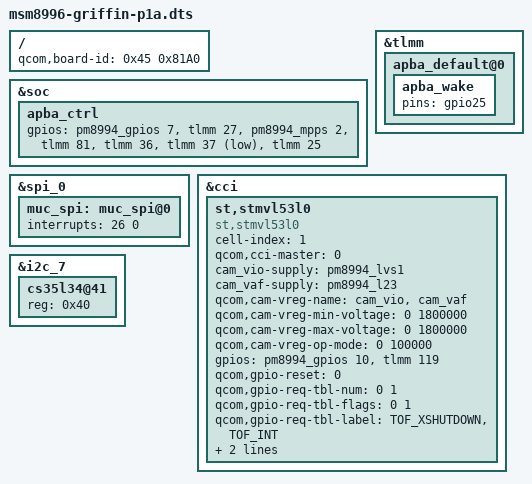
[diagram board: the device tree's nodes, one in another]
/* Copyright (c) 2015, Motorola Mobility Inc. All rights reserved.
 *
 * This program is free software; you can redistribute it and/or modify
 * it under the terms of the GNU General Public License version 2 and
 * only version 2 as published by the Free Software Foundation.
 *
 * This program is distributed in the hope that it will be useful,
 * but WITHOUT ANY WARRANTY; without even the implied warranty of
 * MERCHANTABILITY or FITNESS FOR A PARTICULAR PURPOSE.  See the
 * GNU General Public License for more details.
 */


/dts-v1/;

#include "msm8996-griffin.dtsi"

/ {
	qcom,board-id = <0x45 0x81A0>;
};

&soc {
	apba_ctrl {
		gpios = <&pm8994_gpios 7 2>, /* APBA_1P1_EN, output-high */
			<&tlmm 27 0>,        /* APBA_BOOTRET, output-low */
			<&pm8994_mpps 2 0>,  /* MOD_MPHY_I2S_EN_N, output-low */
			<&tlmm 81 2>,        /* MOD_MPHY_I2S_SEL, output-high */
			<&tlmm 36 0>,       /* APBA_RESET_N, output-low */
			<&tlmm 37 1>,       /* APBA_INT_N, in */
			<&tlmm 25 2>;        /* APBA_WAKE, output-high */
	};
};

&spi_0 {
	muc_spi: muc_spi@0 {
		interrupts = <26 0>;
	};
};

&tlmm {
	apba_default@0 {
		apba_wake {
			pins = "gpio25";
		};
	};
};

&cci {
	st,stmvl53l0 {
		cell-index = <1>;
		compatible = "st,stmvl53l0";
		qcom,cci-master = <0>;
		cam_vio-supply = <&pm8994_lvs1>;
		cam_vaf-supply = <&pm8994_l23>;
		qcom,cam-vreg-name = "cam_vio", "cam_vaf";
		qcom,cam-vreg-min-voltage = <0 1800000>;
		qcom,cam-vreg-max-voltage = <0 1800000>;
		qcom,cam-vreg-op-mode = <0 100000>;
		gpios =<&pm8994_gpios 10 0>,
			  <&tlmm 119 0>;
		qcom,gpio-reset = <0>;
		qcom,gpio-req-tbl-num = <0 1>;
		qcom,gpio-req-tbl-flags = <0 1>;
		qcom,gpio-req-tbl-label = "TOF_XSHUTDOWN","TOF_INT";
		pinctrl-names = "laser_default", "laser_suspend";
		pinctrl-0 = <&laser_active>;
		pinctrl-1 = <&laser_suspend>;
	};
};

&i2c_7 {
	cs35l34@41 {
		reg = <0x40>;
	};
};
